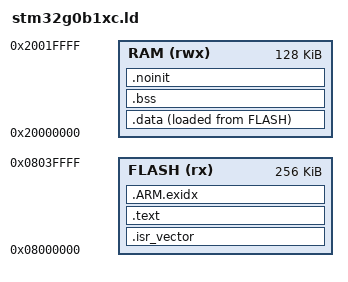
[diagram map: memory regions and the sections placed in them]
/*
 * STM32G0B1RCT6（Flash 256 KB）用linker script
 *
 * SRAMはCMSIS device headerのSRAM_SIZE_MAXに合わせて128 KBとする。
 * .noinitはreset後も消さない領域で、bootloader移行要求などsoftware resetをまたぐ印に使う。
 */
ENTRY(Reset_Handler)

MEMORY
{
    FLASH (rx)  : ORIGIN = 0x08000000, LENGTH = 256K
    RAM   (rwx) : ORIGIN = 0x20000000, LENGTH = 128K
}

_estack = ORIGIN(RAM) + LENGTH(RAM);
_min_stack_size = 0x1000;

SECTIONS
{
    .isr_vector :
    {
        . = ALIGN(4);
        KEEP(*(.isr_vector))
        . = ALIGN(4);
    } > FLASH

    .text :
    {
        . = ALIGN(4);
        *(.text*)
        *(.rodata*)
        KEEP(*(.init))
        KEEP(*(.fini))
        . = ALIGN(4);
    } > FLASH

    .ARM.exidx :
    {
        *(.ARM.exidx* .gnu.linkonce.armexidx.*)
    } > FLASH

    _sidata = LOADADDR(.data);

    .data :
    {
        . = ALIGN(4);
        _sdata = .;
        *(.data*)
        . = ALIGN(4);
        _edata = .;
    } > RAM AT > FLASH

    .bss (NOLOAD) :
    {
        . = ALIGN(4);
        _sbss = .;
        *(.bss*)
        *(COMMON)
        . = ALIGN(4);
        _ebss = .;
    } > RAM

    .noinit (NOLOAD) :
    {
        . = ALIGN(4);
        *(.noinit*)
        . = ALIGN(4);
    } > RAM

    . = ALIGN(8);
    end = .;
    _end = .;

    ASSERT(_end + _min_stack_size <= _estack, "RAM overflow")
}
